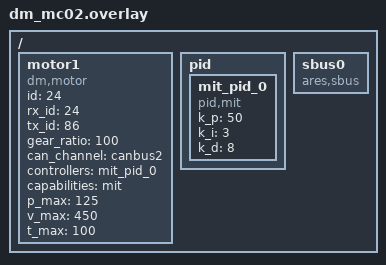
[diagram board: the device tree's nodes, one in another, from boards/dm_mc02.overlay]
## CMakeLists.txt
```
# SPDX-License-Identifier: Apache-2.0

cmake_minimum_required(VERSION 3.20.0)
set(CMAKE_CXX_STANDARD 17)
find_package(Zephyr REQUIRED HINTS $ENV{ZEPHYR_BASE})
project(motor)

FILE(GLOB app_sources src/*.c)


target_sources(app PRIVATE ${app_sources})
target_include_directories(app PRIVATE ${ZEPHYR_BASE}/include)
target_include_directories(app PRIVATE ${CMAKE_CURRENT_SOURCE_DIR}/include)
target_include_directories(app PRIVATE ${CMAKE_CURRENT_SOURCE_DIR}/dts)
```

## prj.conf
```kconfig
# 启用线程分析器
CONFIG_THREAD_ANALYZER=y
CONFIG_THREAD_ANALYZER_USE_LOG=y
CONFIG_THREAD_ANALYZER_USE_PRINTK=n
CONFIG_THREAD_NAME=y
# CONFIG_THREAD_ANALYZER_AUTO=y
# CONFIG_THREAD_ANALYZER_AUTO_INTERVAL=5
CONFIG_THREAD_ANALYZER_LOG_LEVEL_INF=y
CONFIG_THREAD_ANALYZER_AUTO_SEPARATE_CORES=n

# 启用 Shell 支持
CONFIG_SHELL=n
CONFIG_SHELL_BACKENDS=n
CONFIG_SHELL_BACKEND_SERIAL=n

# 启用 UART 控制台
CONFIG_UART_CONSOLE=y

# 禁用 SEGGER RTT
CONFIG_USE_SEGGER_RTT=n

# 启用事件支持
CONFIG_EVENTS=y

# 启用控制台支持
CONFIG_CONSOLE=y

# 启用日志系统
CONFIG_LOG=y
CONFIG_LOG_MODE_IMMEDIATE=y
CONFIG_LOG_PRINTK=y
CONFIG_LOG_BACKEND_UART=y
# CONFIG_LOG_MODE_IMMEDIATE=y

# 启用串行支持
CONFIG_SERIAL=y

# 禁用优化
CONFIG_NO_OPTIMIZATIONS=y

# 启用驱动
CONFIG_MOTOR=y
CONFIG_MOTOR_DM=y
CONFIG_MOTOR_LOG_LEVEL=4
CONFIG_CAN=y
CONFIG_MOTOR_INIT_PRIORITY=90

CONFIG_ARES=y

# use ASYNC uart API
CONFIG_SERIAL=y
CONFIG_UART_ASYNC_API=y
CONFIG_UART_INTERRUPT_DRIVEN=y

CONFIG_DMA=y
CONFIG_DMA_STM32=y  # STM32 DMA 驱动
CONFIG_UART_STM32=y # STM32 UART 驱动
# CONFIG_STM32_UART_DMA=y

# CONFIG_HAS_STM32CUBE=y
# CONFIG_USE_STM32_HAL_DMA=y
CONFIG_SPI=y
CONFIG_SPI_STM32=y
```

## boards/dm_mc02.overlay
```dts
/ {
	motor1: motor1{
		compatible = "dm,motor";
		id = <24>;
		rx_id = <24>;
		tx_id = <86>;
		gear_ratio = <100>;
		status = "okay";
		can_channel = <&canbus2>;
		controllers = <&mit_pid_0>;
		capabilities = "mit";
		p_max = <125>;
		v_max = <450>;
		t_max = <100>;
	};

	pid {
		mit_pid_0: mit_pid_0 {
			#controller-cells = <0>;
			compatible = "pid,mit";
			k_p = <50>;
			k_i = <3>;
			k_d = <8>;
		};
	};
	sbus0: sbus0 {
		compatible = "ares,sbus";
		status = "okay";
	};
};
```

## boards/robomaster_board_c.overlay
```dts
/ {
	motor1: motor1{
		compatible = "dm,motor";
		id = <24>;
		rx_id = <24>;
		tx_id = <86>;
		gear_ratio = <100>;
		status = "okay";
		can_channel = <&canbus1>;
		controllers = <&mit_pid_0>;
		capabilities = "mit";
		p_max = <125>;
		v_max = <450>;
		t_max = <100>;
	};

	pid {
		mit_pid_0: mit_pid_0 {
			#controller-cells = <0>;
			compatible = "pid,mit";
			k_p = <50>;
			k_i = <3>;
			k_d = <8>;
		};
	};
	sbus0: sbus0 {
		compatible = "ares,sbus";
		status = "okay";
	};
};
```

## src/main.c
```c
/*
 * Copyright (c) 2024 ttwards <12411711@mail.sustech.edu.cn>
 *
 * SPDX-License-Identifier: Apache-2.0
 */

#include <stddef.h>
#include <stdint.h>
#include <zephyr/device.h>
#include <zephyr/logging/log.h>
#include <zephyr/devicetree.h>
#include <zephyr/drivers/can.h>
#include <zephyr/debug/thread_analyzer.h>
#include <zephyr/kernel.h>
#include <zephyr/sys/printk.h>
#include <zephyr/drivers/motor.h>
#include <ares/board/init.c>

LOG_MODULE_REGISTER(main, LOG_LEVEL_DBG);

#define HIGH_BYTE(x)           ((x) >> 8)
#define LOW_BYTE(x)            ((x) & 0xFF)
#define COMBINE_HL8(HIGH, LOW) ((HIGH << 8) + LOW)

/* Devicetree */
#define CANBUS_NODE DT_CHOSEN(zephyr_canbus)
#define CAN1_NODE   DT_INST(0, vnd_canbus)
#define MOTOR1_NODE DT_INST(0, dm_motor)

const struct device *can_dev = DEVICE_DT_GET(CANBUS_NODE);
const struct device *motor1 = DEVICE_DT_GET(MOTOR1_NODE);

/* CAN Feedback to console*/
K_THREAD_STACK_DEFINE(feedback_stack_area, 2048); // 定义线程栈
void console_feedback(void *arg1, void *arg2, void *arg3)
{
	while (1) {
		thread_analyzer_print(NULL);

		LOG_INF("rpm: motor1: %.2f\n", (double)motor_get_speed(motor1));
		k_msleep(500);
	}
}

int main(void)
{
	board_init();

	motor_set_mode(motor1, MIT);
	motor_control(motor1, ENABLE_MOTOR);
	motor_set_speed(motor1, 45);

	/* Start Feedback thread*/
	struct k_thread feedback_thread_data;
	k_thread_create(&feedback_thread_data,
			feedback_stack_area, // 修改为 can_send_stack_area
			K_THREAD_STACK_SIZEOF(feedback_stack_area), console_feedback,
			(void *)motor1, NULL, NULL, 0, 0, K_MSEC(300));

	while (1) {
		k_msleep(500);
	}
}
```
